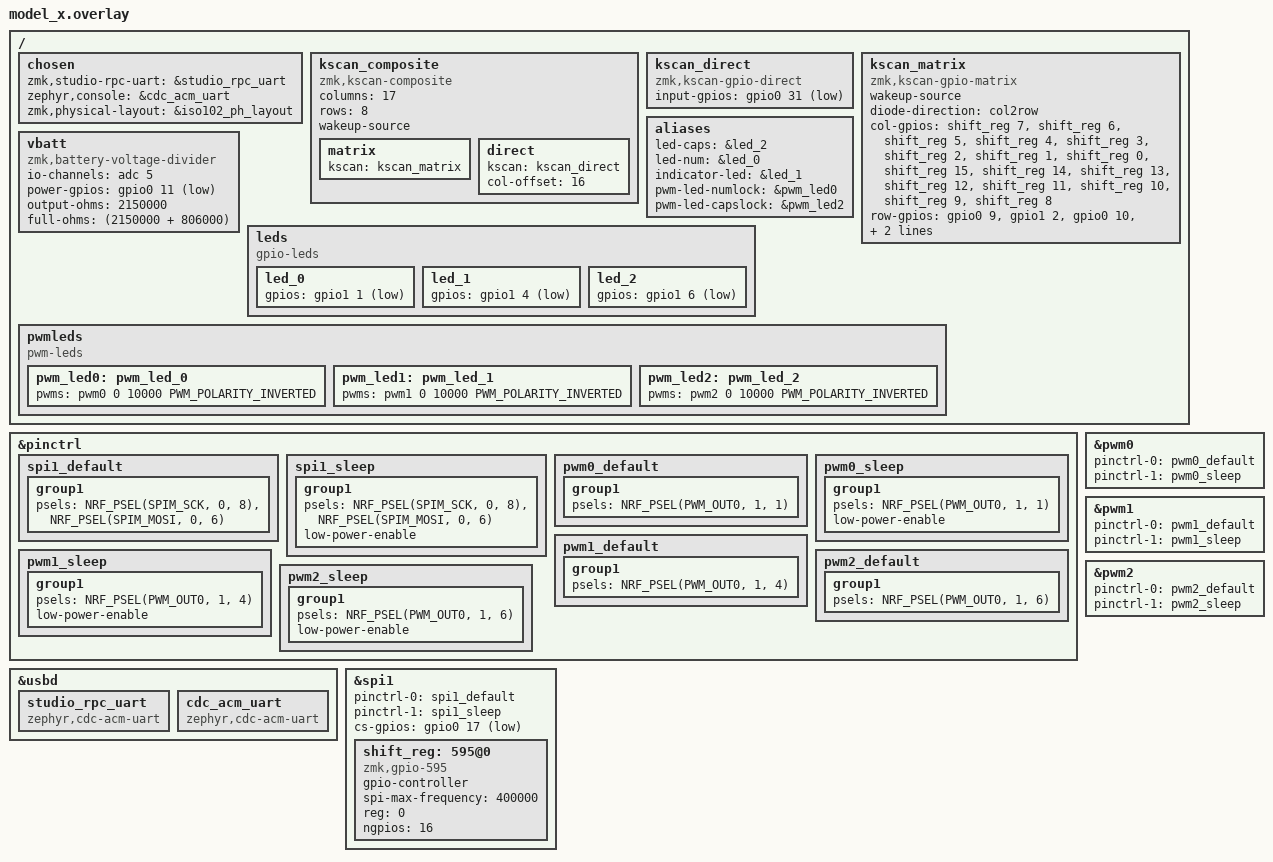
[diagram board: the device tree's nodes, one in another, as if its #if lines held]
#include <dt-bindings/zmk/matrix_transform.h>
#include <dt-bindings/led/led.h>
#include <physical_layouts.dtsi>

#include "config.dtsi"
#ifdef DFU_IN_KEYMAP
#include "../../common/modelm_posmap_103.dtsi"
#define UNIFIED_KSCAN kscan_composite
#else
#include "../../common/modelm_posmap_102.dtsi"
#define UNIFIED_KSCAN kscan_matrix
#endif
#include "../../common/layouts/modelm_ansi101.dtsi"
#include "../../common/layouts/modelm_iso102.dtsi"
#include "../../common/layouts/modelm_ansi84.dtsi"
#include "../../common/layouts/modelm_iso85.dtsi"


/ {
    chosen {
        zmk,studio-rpc-uart = &studio_rpc_uart;
        zephyr,console = &cdc_acm_uart;
        zmk,physical-layout = &iso102_ph_layout;
    };

// Include DFU button if needed
#ifdef DFU_IN_KEYMAP
    // Combine matrix and direct GPIO to integrate DFU button neat the USB connector
    kscan_composite: kscan_composite {
        compatible = "zmk,kscan-composite";
        columns = <17>;
        rows = <8>;
        wakeup-source;

        // Include the matrix driver
        matrix {
            kscan = <&kscan_matrix>;
        };

        // Include the direct GPIO driver...
        direct {
            kscan = <&kscan_direct>;
            col-offset = <16>;
        };
    };

    kscan_direct: kscan_direct {
        compatible = "zmk,kscan-gpio-direct";
        // DFU button is on P0.31 GPIO-direct pin active-low, pull high
        input-gpios
            = <&gpio0 31 (GPIO_ACTIVE_LOW | GPIO_PULL_UP)> // DFU
            ;
        /*
         * A direct pin defined in the input-gpios property is considered a column
         * when used in a matrix transform; e.g. the 5th pin on the list can be referred to using RC(0,4).
         */
    };

#endif    

    kscan_matrix: kscan_matrix {
        compatible = "zmk,kscan-gpio-matrix";
        wakeup-source;
        diode-direction = "col2row";

        col-gpios = 
            <&shift_reg 7  (GPIO_ACTIVE_HIGH)>, // col 0
            <&shift_reg 6  (GPIO_ACTIVE_HIGH)>, // col 1
            <&shift_reg 5  (GPIO_ACTIVE_HIGH)>, // col 2
            <&shift_reg 4  (GPIO_ACTIVE_HIGH)>, // col 3
            <&shift_reg 3  (GPIO_ACTIVE_HIGH)>, // col 4
            <&shift_reg 2  (GPIO_ACTIVE_HIGH)>, // col 5
            <&shift_reg 1  (GPIO_ACTIVE_HIGH)>, // col 6
            <&shift_reg 0  (GPIO_ACTIVE_HIGH)>, // col 7
            <&shift_reg 15 (GPIO_ACTIVE_HIGH)>, // col 8
            <&shift_reg 14 (GPIO_ACTIVE_HIGH)>, // col 9
            <&shift_reg 13 (GPIO_ACTIVE_HIGH)>, // col 10
            <&shift_reg 12 (GPIO_ACTIVE_HIGH)>, // col 11
            <&shift_reg 11 (GPIO_ACTIVE_HIGH)>, // col 12
            <&shift_reg 10 (GPIO_ACTIVE_HIGH)>, // col 13
            <&shift_reg 9  (GPIO_ACTIVE_HIGH)>, // col 14
            <&shift_reg 8  (GPIO_ACTIVE_HIGH)>  // col 15
        ;

        row-gpios =
            <&gpio0 9  (GPIO_ACTIVE_HIGH | GPIO_PULL_DOWN)>, // row 0
            <&gpio1 2  (GPIO_ACTIVE_HIGH | GPIO_PULL_DOWN)>, // row 1
            <&gpio0 10 (GPIO_ACTIVE_HIGH | GPIO_PULL_DOWN)>, // row 2
            <&gpio1 7  (GPIO_ACTIVE_HIGH | GPIO_PULL_DOWN)>, // row 3
            <&gpio1 11 (GPIO_ACTIVE_HIGH | GPIO_PULL_DOWN)>, // row 4
            <&gpio1 13 (GPIO_ACTIVE_HIGH | GPIO_PULL_DOWN)>, // row 5
            <&gpio1 15 (GPIO_ACTIVE_HIGH | GPIO_PULL_DOWN)>, // row 6
            <&gpio0 2  (GPIO_ACTIVE_HIGH | GPIO_PULL_DOWN)>  // row 7
        ;
    };

    vbatt: vbatt {
        compatible = "zmk,battery-voltage-divider";
        io-channels = <&adc 5>;
        power-gpios = <&gpio0 11 (GPIO_OPEN_DRAIN | GPIO_ACTIVE_LOW)>;
        output-ohms = <2150000>;
        full-ohms = <(2150000 + 806000)>;
    };

};

&pinctrl {
    spi1_default: spi1_default {
        group1 {
            psels = <NRF_PSEL(SPIM_SCK, 0, 8)>,
                <NRF_PSEL(SPIM_MOSI, 0, 6)>;
        };
    };

    spi1_sleep: spi1_sleep {
        group1 {
            psels = <NRF_PSEL(SPIM_SCK, 0, 8)>,
                <NRF_PSEL(SPIM_MOSI, 0, 6)>;
            low-power-enable;
        };
    };
	
	pwm0_default: pwm0_default {
        group1 {
            psels = <NRF_PSEL(PWM_OUT0, 1, 1)>;
        };
    };
	
    pwm0_sleep: pwm0_sleep {
        group1 {
            psels = <NRF_PSEL(PWM_OUT0, 1, 1)>;
            low-power-enable;
        };
    };

	pwm1_default: pwm1_default {
        group1 {
            psels = <NRF_PSEL(PWM_OUT0, 1, 4)>;
        };
    };
	
    pwm1_sleep: pwm1_sleep {
        group1 {
            psels = <NRF_PSEL(PWM_OUT0, 1, 4)>;
            low-power-enable;
        };
    };
	
	pwm2_default: pwm2_default {
        group1 {
            psels = <NRF_PSEL(PWM_OUT0, 1, 6)>;
        };
    };
	
    pwm2_sleep: pwm2_sleep {
        group1 {
            psels = <NRF_PSEL(PWM_OUT0, 1, 6)>;
            low-power-enable;
        };
    };

};

zephyr_udc0: &usbd {
    status = "okay";
    studio_rpc_uart: studio_rpc_uart {
        compatible = "zephyr,cdc-acm-uart";
    };
    cdc_acm_uart: cdc_acm_uart {
        compatible = "zephyr,cdc-acm-uart";
    };
};

&pwm0 {
    status = "okay";
    pinctrl-0 = <&pwm0_default>;
    pinctrl-1 = <&pwm0_sleep>;
    pinctrl-names = "default", "sleep";
};

&pwm1 {
    status = "okay";
    pinctrl-0 = <&pwm1_default>;
    pinctrl-1 = <&pwm1_sleep>;
    pinctrl-names = "default", "sleep";
};

&pwm2 {
    status = "okay";
    pinctrl-0 = <&pwm2_default>;
    pinctrl-1 = <&pwm2_sleep>;
    pinctrl-names = "default", "sleep";
};
/*
&gpio0 {
    extpwr_pull: extpwr_pull {
        gpio-hog;
        gpios = <13 GPIO_ACTIVE_HIGH>;  // might need to swap this or the next, not sure
        output-low;
        line-name = "Disable ext power pin";
    };
};
*/

&spi1 {
    // Enable the SPI interface and configure the CS (Chip Select) pin
    status = "okay";
    pinctrl-0 = <&spi1_default>; // Default pin configuration
    pinctrl-1 = <&spi1_sleep>;   // Low power pin configuration
    pinctrl-names = "default", "sleep"; // Names of the pin configurations
    //wakeup-source; 
    cs-gpios = <&gpio0 17 GPIO_ACTIVE_LOW>; // Pin 0.17 for CS (Chip Select), active low

    shift_reg: 595@0 {
        // Configure the 74HC595 shift register
        compatible = "zmk,gpio-595"; // Specify the compatible device
        status = "okay";
        //wakeup-source; 
        gpio-controller;
        spi-max-frequency = <400000>; // Maximum SPI frequency (4 MHz)
        #gpio-cells = <2>;
        reg = <0>; // SPI device address
        #gpio-cells = <2>;
        ngpios = <16>;
    };

};

/ {
    aliases {
		led-caps = &led_2;
		led-num = &led_0;
        /* Use 'Scroll Lock' LED as BLE/Battery blink indicator instead */
		//led-scroll = &led_1;
        indicator-led = &led_1;
    };

    leds {
        compatible = "gpio-leds";
        status = "okay";
        led_0: led_0 {
            gpios = <&gpio1 1 GPIO_ACTIVE_LOW>;
        };
        led_1: led_1 {
            gpios = <&gpio1 4 GPIO_ACTIVE_LOW>;
        };
        led_2: led_2 {
            gpios = <&gpio1 6 GPIO_ACTIVE_LOW>;
        };
    };
};

/ {

    aliases {
        pwm-led-numlock = &pwm_led0;
        pwm-led-capslock = &pwm_led2;
        //pwm-led-scrolllock = &pwm_led1;
    };

	pwmleds {
		compatible = "pwm-leds";
		pwm_led0: pwm_led_0 {
			pwms = <&pwm0 0 10000 PWM_POLARITY_INVERTED>;
		};

		pwm_led1: pwm_led_1 {
			pwms = <&pwm1 0 10000 PWM_POLARITY_INVERTED>;
		};

		pwm_led2: pwm_led_2 {
			pwms = <&pwm2 0 10000 PWM_POLARITY_INVERTED>;
		};
	};

};
